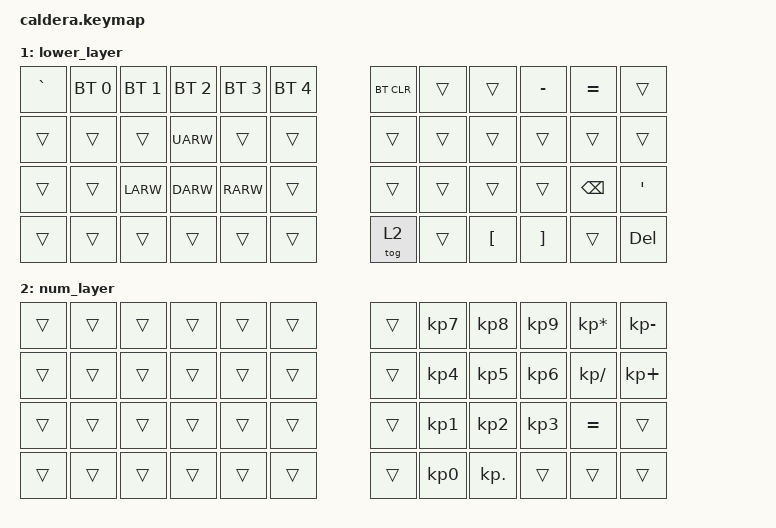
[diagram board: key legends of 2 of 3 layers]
#include <behaviors.dtsi>
#include <dt-bindings/zmk/keys.h>
#include <dt-bindings/zmk/bt.h>

/ {
        keymap {
                compatible = "zmk,keymap";

                default_layer {
// ---------------------------------------------------------------------------------
// |  ESC |  1  |  2  |  3  |  4  |  5  |     |  6  |  7  |  8  |  9  |  0  | BKSP |
// |  TAB |  Q  |  W  |  E  |  R  |  T  |     |  Y  |  U  |  I  |  O  |  P  |  \   |
// | CAPS |  A  |  S  |  D  |  F  |  G  |     |  H  |  J  |  K  |  L  |  ;  |  ENT |
// | SHFT |  Z  |  X  |  C  |  V  |  B  |     |  N  |  M  |  ,  |  .  |  /  | SHFT |
// | CTRL | ALT | GUI | SPC | GUI | MO 1|     | MO 1| SPC |LARW |UARW |DARW | RARW |
                        bindings = <
   &kp ESC    &kp N1    &kp N2    &kp N3     &kp N4     &kp N5               &kp N6     &kp N7    &kp N8     &kp N9    &kp N0    &kp BSPC
   &kp TAB    &kp Q     &kp W     &kp E      &kp R      &kp T                &kp Y      &kp U     &kp I      &kp O     &kp P     &kp BSLH
   &kp CAPS   &kp A     &kp S     &kp D      &kp F      &kp G                &kp H      &kp J     &kp K      &kp L     &kp SEMI  &kp RET
   &kp LSHFT  &kp Z     &kp X     &kp C      &kp V      &kp B                &kp N      &kp M     &kp COMMA  &kp DOT   &kp FSLH  &kp RSHFT
   &kp LCTRL  &kp LALT  &kp LGUI  &kp SPACE  &kp LGUI   &mo 1                &mo 1      &kp SPACE &kp LARW   &kp UARW  &kp DARW  &kp RARW
                        >;
                };
                lower_layer {
// ------------------------------------------------------------------------------------------------------------
// |   `   |  BT1  |  BT2  |  BT3  |  BT4  |  BT5  |          | BTCLR |       |       |   -   |   =   |       |
// |       |       |       |  UARW |       |       |          |       |       |       |       |       |       |
// |       |       |  LARW |  DARW |  RARW |       |          |       |       |       |       |  BKSP |   ‘   |
// |       |       |       |       |       |       |          | TOG 2 |       |   [   |    ]  |       |  DEL  |
                        bindings = <
   &kp GRAVE &bt BT_SEL 0   &bt BT_SEL 1   &bt BT_SEL 2   &bt BT_SEL 3   &bt BT_SEL 4           &bt BT_CLR &trans    &trans   &kp MINUS &kp EQUAL &trans
   &trans    &trans         &trans         &kp UARW       &trans         &trans                 &trans     &trans    &trans   &trans    &trans    &trans
   &trans    &trans         &kp LARW       &kp DARW       &kp RARW       &trans                 &trans     &trans    &trans   &trans    &kp BSPC  &kp APOS
   &trans    &trans         &trans         &trans         &trans         &trans                 &tog 2     &trans    &kp LBKT &kp RBKT  &trans    &kp DEL
                        >;
                };
                num_layer {
// ------------------------------------------------------------------------------------------------------------
// |       |       |       |       |       |       |          |       |   7   |   8   |   9   |   *   |   -   |
// |       |       |       |       |       |       |          |       |   4   |   5   |   6   |   /   |   +   |
// |       |       |       |       |       |       |          |       |   1   |   2   |   3   |   =   |       |
// |       |       |       |       |       |       |          |       |   0   |   .   |       |       |       |
                        bindings = <
   &trans    &trans         &trans         &trans         &trans         &trans                 &trans   &kp KP_N7 &kp KP_N8  &kp KP_N9  &kp KP_MULTIPLY &kp KP_MINUS
   &trans    &trans         &trans         &trans         &trans         &trans                 &trans   &kp KP_N4 &kp KP_N5  &kp KP_N6  &kp KP_DIVIDE   &kp KP_PLUS
   &trans    &trans         &trans         &trans         &trans         &trans                 &trans   &kp KP_N1 &kp KP_N2  &kp KP_N3  &kp EQUAL       &trans
   &trans    &trans         &trans         &trans         &trans         &trans                 &trans   &kp KP_N0 &kp KP_DOT &trans     &trans          &trans
                        >;
                };

        };
};
